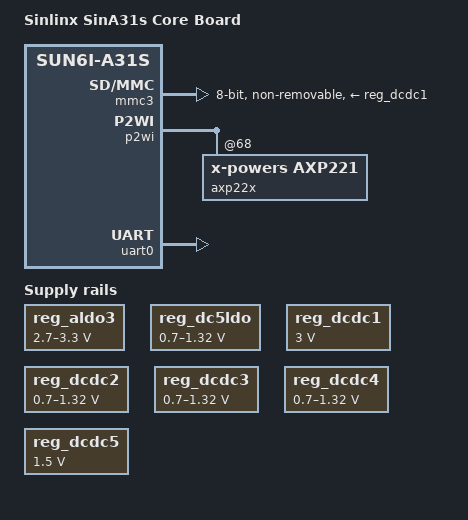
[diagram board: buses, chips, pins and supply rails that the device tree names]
/dts-v1/;
#include "sun6i-a31s.dtsi"
#include "sunxi-common-regulators.dtsi"
#include <dt-bindings/gpio/gpio.h>
/ {
	model = "Sinlinx SinA31s Core Board";
	compatible = "sinlinx,sina31s", "allwinner,sun6i-a31s";
	aliases {
		serial0 = &uart0;
	};
};
&cpu0 {
	cpu-supply = <&reg_dcdc3>;
};
&mmc3 {
	pinctrl-names = "default";
	pinctrl-0 = <&mmc3_8bit_emmc_pins>;
	vmmc-supply = <&reg_dcdc1>;
	vqmmc-supply = <&reg_dcdc1>;
	bus-width = <8>;
	non-removable;
	cap-mmc-hw-reset;
	status = "okay";
};
&p2wi {
	status = "okay";
	axp22x: pmic@68 {
		compatible = "x-powers,axp221";
		reg = <0x68>;
		interrupt-parent = <&r_intc>;
		interrupts = <GIC_SPI 32 IRQ_TYPE_LEVEL_LOW>;
	};
};
#include "axp22x.dtsi"
&reg_aldo3 {
	regulator-always-on;
	regulator-min-microvolt = <2700000>;
	regulator-max-microvolt = <3300000>;
	regulator-name = "avcc";
};
&reg_dc5ldo {
	regulator-min-microvolt = <700000>;
	regulator-max-microvolt = <1320000>;
	regulator-name = "vdd-cpus";
};
&reg_dcdc1 {
	regulator-always-on;
	regulator-min-microvolt = <3000000>;
	regulator-max-microvolt = <3000000>;
	regulator-name = "vcc-3v0";
};
&reg_dcdc2 {
	regulator-min-microvolt = <700000>;
	regulator-max-microvolt = <1320000>;
	regulator-name = "vdd-gpu";
};
&reg_dcdc3 {
	regulator-always-on;
	regulator-min-microvolt = <700000>;
	regulator-max-microvolt = <1320000>;
	regulator-name = "vdd-cpu";
};
&reg_dcdc4 {
	regulator-always-on;
	regulator-min-microvolt = <700000>;
	regulator-max-microvolt = <1320000>;
	regulator-name = "vdd-sys-dll";
};
&reg_dcdc5 {
	regulator-always-on;
	regulator-min-microvolt = <1500000>;
	regulator-max-microvolt = <1500000>;
	regulator-name = "vcc-dram";
};
&uart0 {
	pinctrl-names = "default";
	pinctrl-0 = <&uart0_ph_pins>;
	status = "okay";
};
